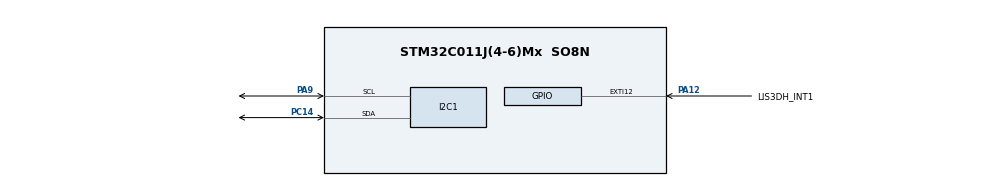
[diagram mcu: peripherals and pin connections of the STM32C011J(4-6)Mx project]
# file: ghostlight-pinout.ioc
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ADC1.NbrOfConversionFlag=0
ADC1.SelectedChannel=ADC_CHANNEL_VREFINT
ADC1.master=1
Dma.ADC1.0.Direction=DMA_PERIPH_TO_MEMORY
Dma.ADC1.0.EventEnable=DISABLE
Dma.ADC1.0.Instance=DMA1_Channel1
Dma.ADC1.0.MemDataAlignment=DMA_MDATAALIGN_HALFWORD
Dma.ADC1.0.MemInc=DMA_MINC_ENABLE
Dma.ADC1.0.Mode=DMA_NORMAL
Dma.ADC1.0.PeriphDataAlignment=DMA_PDATAALIGN_HALFWORD
Dma.ADC1.0.PeriphInc=DMA_PINC_DISABLE
Dma.ADC1.0.Polarity=HAL_DMAMUX_REQ_GEN_RISING
Dma.ADC1.0.Priority=DMA_PRIORITY_LOW
Dma.ADC1.0.RequestNumber=1
Dma.ADC1.0.SignalID=NONE
Dma.ADC1.0.SyncEnable=DISABLE
Dma.ADC1.0.SyncPolarity=HAL_DMAMUX_SYNC_NO_EVENT
Dma.ADC1.0.SyncRequestNumber=1
Dma.ADC1.0.SyncSignalID=NONE
Dma.I2C1_RX.1.Direction=DMA_PERIPH_TO_MEMORY
Dma.I2C1_RX.1.EventEnable=DISABLE
Dma.I2C1_RX.1.Instance=DMA1_Channel2
Dma.I2C1_RX.1.MemDataAlignment=DMA_MDATAALIGN_BYTE
Dma.I2C1_RX.1.MemInc=DMA_MINC_ENABLE
Dma.I2C1_RX.1.Mode=DMA_NORMAL
Dma.I2C1_RX.1.PeriphDataAlignment=DMA_PDATAALIGN_BYTE
Dma.I2C1_RX.1.PeriphInc=DMA_PINC_DISABLE
Dma.I2C1_RX.1.Polarity=HAL_DMAMUX_REQ_GEN_RISING
Dma.I2C1_RX.1.Priority=DMA_PRIORITY_LOW
Dma.I2C1_RX.1.RequestNumber=1
Dma.I2C1_RX.1.SignalID=NONE
Dma.I2C1_RX.1.SyncEnable=DISABLE
Dma.I2C1_RX.1.SyncPolarity=HAL_DMAMUX_SYNC_NO_EVENT
Dma.I2C1_RX.1.SyncRequestNumber=1
Dma.I2C1_RX.1.SyncSignalID=NONE
Dma.I2C1_TX.2.Direction=DMA_MEMORY_TO_PERIPH
Dma.I2C1_TX.2.EventEnable=DISABLE
Dma.I2C1_TX.2.Instance=DMA1_Channel3
Dma.I2C1_TX.2.MemDataAlignment=DMA_MDATAALIGN_BYTE
Dma.I2C1_TX.2.MemInc=DMA_MINC_ENABLE
Dma.I2C1_TX.2.Mode=DMA_NORMAL
Dma.I2C1_TX.2.PeriphDataAlignment=DMA_PDATAALIGN_BYTE
Dma.I2C1_TX.2.PeriphInc=DMA_PINC_DISABLE
Dma.I2C1_TX.2.Polarity=HAL_DMAMUX_REQ_GEN_RISING
Dma.I2C1_TX.2.Priority=DMA_PRIORITY_LOW
Dma.I2C1_TX.2.RequestNumber=1
Dma.I2C1_TX.2.SignalID=NONE
Dma.I2C1_TX.2.SyncEnable=DISABLE
Dma.I2C1_TX.2.SyncPolarity=HAL_DMAMUX_SYNC_NO_EVENT
Dma.I2C1_TX.2.SyncRequestNumber=1
Dma.I2C1_TX.2.SyncSignalID=NONE
Dma.Request0=ADC1
Dma.Request1=I2C1_RX
Dma.Request2=I2C1_TX
I2C1.Timing=0x00402D41
Mcu.Family=STM32C0
Mcu.Name=STM32C011J(4-6)Mx
Mcu.Package=SO8N
NVIC.DMA1_Channel1_IRQn=true\:0\:0\:false\:false\:true\:false\:true\:true
NVIC.DMA1_Channel2_3_IRQn=true\:0\:0\:false\:false\:true\:false\:true\:true
NVIC.EXTI4_15_IRQn=true\:0\:0\:false\:false\:true\:true\:true\:true
NVIC.TIM14_IRQn=true\:0\:0\:false\:false\:true\:true\:true\:true
PA12\ [PA10].GPIO_Label=LIS3DH_INT1
PA12\ [PA10].Signal=GPXTI12
PA13.Mode=Serial_Wire
PA13.Signal=DEBUG_SWDIO
PA14-BOOT0.Mode=Serial_Wire
PA14-BOOT0.Signal=DEBUG_SWCLK
PA8__PA11\ [PA9].StandardMode=true
PA9\ [PA11].Mode=I2C
PA9\ [PA11].Signal=I2C1_SCL
PC14-OSCX_IN\ (PC14).Mode=I2C
PC14-OSCX_IN\ (PC14).Signal=I2C1_SDA
PC14-OSCX_IN\ (PC14)__PB7.StandardMode=true
PC15-OSCX_OUT\ (PC15)__PA14-BOOT0__PB6.StandardMode=true
PF2-NRST__PA0__PA1__PA2.StandardMode=true
ProjectManager.HeapSize=0x200
ProjectManager.StackSize=0x400
ProjectManager.TargetToolchain=STM32CubeIDE
RCC.ADCFreq_Value=12000000
RCC.AHBFreq_Value=12000000
RCC.CortexFreq_Value=12000000
RCC.EXTERNAL_CLOCK_VALUE=12288000
RCC.HCLKFreq_Value=12000000
RCC.HSE_VALUE=8000000
RCC.HSI_VALUE=48000000
RCC.LSE_VALUE=32768
RCC.SYSCLKFreq_VALUE=12000000
VP_ADC1_Vref_Input.Mode=IN-Vrefint
VP_SYS_VS_PINREMAP.Mode=PINREMAP
VP_TIM14_VS_ClockSourceINT.Mode=Enable_Timer
board=custom

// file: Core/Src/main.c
/* USER CODE BEGIN Header */
/**
 ******************************************************************************
 * @file           : main.c
 * @brief          : Main program body
 ******************************************************************************
 * @attention
 *
 * Copyright (c) 2026 STMicroelectronics.
 * All rights reserved.
 *
 * This software is licensed under terms that can be found in the LICENSE file
 * in the root directory of this software component.
 * If no LICENSE file comes with this software, it is provided AS-IS.
 *
 ******************************************************************************
 */
/* USER CODE END Header */
#include "main.h"
#include "adc.h"
#include "dma.h"
#include "i2c.h"
#include "tim.h"
#include "gpio.h"

/* USER CODE BEGIN Includes */
#include "LP5817.h"
/* USER CODE END Includes */

void SystemClock_Config(void);

/* USER CODE BEGIN 0 */
void handleI2CErr(uint8_t error_code) {
	//HAL_GPIO_WritePin(LIVE_GPIO_Port, LIVE_Pin, RESET);
	// Check if any error occurred (Bit 0 is our 'Error Present' marker)
	if (error_code) {
		/*if (error_code == HAL_ERROR) {
			HAL_GPIO_WritePin(I2C_ERROR_GPIO_Port, I2C_ERROR_Pin, SET);
		} else if (error_code == HAL_BUSY) {
			// Bit 2 of error_code corresponds to LP5817 Bit 1 (LED Short)
			HAL_GPIO_WritePin(FLAG_GPIO_Port, FLAG_Pin, SET);
		} else if (error_code == HAL_TIMEOUT) {
			HAL_GPIO_WritePin(I2C_ERROR_GPIO_Port, I2C_ERROR_Pin, SET);
			HAL_GPIO_WritePin(FLAG_GPIO_Port, FLAG_Pin, SET);
		} else {
			HAL_GPIO_WritePin(LIVE_GPIO_Port, LIVE_Pin, SET);
			//error is in flags from
			if (0 != (error_code & (1 << 2))) {
				HAL_GPIO_WritePin(I2C_ERROR_GPIO_Port, I2C_ERROR_Pin, SET);
			}
			if (0 != (error_code & (1 << 3))) {
				HAL_GPIO_WritePin(FLAG_GPIO_Port, FLAG_Pin, SET);
			}
		}*/

		// If it was just a raw I2C communication error (code was 1),
		// we might want a different indication, but we always end here:
		while (1) {
		}
	}
}
/* USER CODE END 0 */

int main(void)
{

  /* MCU Configuration--------------------------------------------------------*/

  /* Reset of all peripherals, Initializes the Flash interface and the Systick. */
  HAL_Init();

  /* Configure the system clock */
  SystemClock_Config();

  /* Initialize all configured peripherals */
  MX_GPIO_Init();
  MX_DMA_Init();
  MX_I2C1_Init();
  MX_ADC1_Init();
  MX_TIM14_Init();
  /* USER CODE BEGIN 2 */

	//HAL_GPIO_WritePin(LIVE_GPIO_Port, LIVE_Pin, RESET);
	HAL_GPIO_WritePin(I2C_ERROR_GPIO_Port, I2C_ERROR_Pin, RESET);
	//HAL_GPIO_WritePin(FLAG_GPIO_Port, FLAG_Pin, RESET);

	uint8_t i2c_err = LP5817_init();
	HAL_Delay(1);
	handleI2CErr(i2c_err);

	HAL_Delay(500);
	if (initPersistentData() != HAL_OK)
	{
		i2c_err = LP5817_setColor(255, 255, 255);
		handleI2CErr(i2c_err);
	}
	else
	{
		switch (getCycleCount() % 3)
		{
		case 0:
			i2c_err = LP5817_setColor(0, 10, 100);
			handleI2CErr(i2c_err);
			break;
		case 1:
			i2c_err = LP5817_setColor(100, 0, 0);
			handleI2CErr(i2c_err);
			break;
		case 2:
			i2c_err = LP5817_setColor(80, 120, 0);
			handleI2CErr(i2c_err);
			break;
		};
	}
  /* USER CODE END 2 */

  /* Infinite loop */
	while (1) {

    /* USER CODE BEGIN 3 */
		HAL_GPIO_TogglePin(I2C_ERROR_GPIO_Port, I2C_ERROR_Pin);
		HAL_Delay(2000);
	}
  /* USER CODE END 3 */
}

void SystemClock_Config(void)
{
  RCC_OscInitTypeDef RCC_OscInitStruct = {0};
  RCC_ClkInitTypeDef RCC_ClkInitStruct = {0};

  __HAL_FLASH_SET_LATENCY(FLASH_LATENCY_0);

  /** Initializes the RCC Oscillators according to the specified parameters
  * in the RCC_OscInitTypeDef structure.
  */
  RCC_OscInitStruct.OscillatorType = RCC_OSCILLATORTYPE_HSI;
  RCC_OscInitStruct.HSIState = RCC_HSI_ON;
  RCC_OscInitStruct.HSIDiv = RCC_HSI_DIV4;
  RCC_OscInitStruct.HSICalibrationValue = RCC_HSICALIBRATION_DEFAULT;
  if (HAL_RCC_OscConfig(&RCC_OscInitStruct) != HAL_OK)
  {
    Error_Handler();
  }

  /** Initializes the CPU, AHB and APB buses clocks
  */
  RCC_ClkInitStruct.ClockType = RCC_CLOCKTYPE_HCLK|RCC_CLOCKTYPE_SYSCLK
                              |RCC_CLOCKTYPE_PCLK1;
  RCC_ClkInitStruct.SYSCLKSource = RCC_SYSCLKSOURCE_HSI;
  RCC_ClkInitStruct.SYSCLKDivider = RCC_SYSCLK_DIV1;
  RCC_ClkInitStruct.AHBCLKDivider = RCC_HCLK_DIV1;
  RCC_ClkInitStruct.APB1CLKDivider = RCC_APB1_DIV1;

  if (HAL_RCC_ClockConfig(&RCC_ClkInitStruct, FLASH_LATENCY_0) != HAL_OK)
  {
    Error_Handler();
  }
}

void Error_Handler(void)
{
	__disable_irq();
	while (1) {
	}
}
